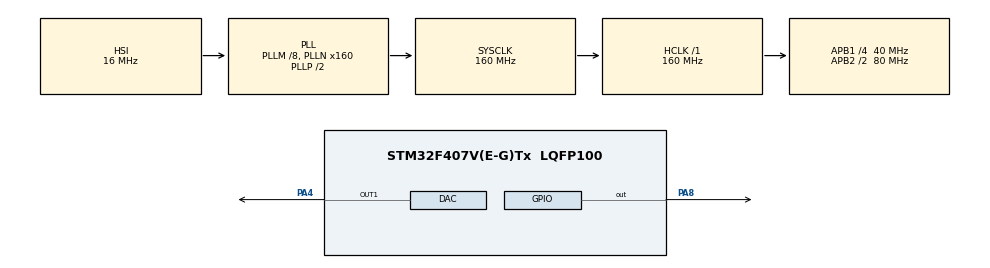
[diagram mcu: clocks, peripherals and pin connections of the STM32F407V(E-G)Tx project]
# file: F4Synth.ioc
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Mcu.Family=STM32F4
Mcu.Name=STM32F407V(E-G)Tx
Mcu.Package=LQFP100
NVIC.PriorityGroup=NVIC_PRIORITYGROUP_4
NVIC.TIM3_IRQn=true\:0\:0\:false\:false\:true\:true\:true\:true
PA13.Mode=Serial_Wire
PA13.Signal=SYS_JTMS-SWDIO
PA14.Mode=Serial_Wire
PA14.Signal=SYS_JTCK-SWCLK
PA4.Signal=COMP_DAC1_group
PA8.Signal=GPIO_Output
PH0-OSC_IN.Mode=HSE-External-Oscillator
PH0-OSC_IN.Signal=RCC_OSC_IN
PH1-OSC_OUT.Mode=HSE-External-Oscillator
PH1-OSC_OUT.Signal=RCC_OSC_OUT
ProjectManager.HeapSize=0x200
ProjectManager.StackSize=0x400
ProjectManager.TargetToolchain=MDK-ARM V5.32
RCC.48MHZClocksFreq_Value=80000000
RCC.AHBFreq_Value=160000000
RCC.APB1CLKDivider=RCC_HCLK_DIV4
RCC.APB1Freq_Value=40000000
RCC.APB1TimFreq_Value=80000000
RCC.APB2CLKDivider=RCC_HCLK_DIV2
RCC.APB2Freq_Value=80000000
RCC.APB2TimFreq_Value=160000000
RCC.CortexFreq_Value=160000000
RCC.HCLKFreq_Value=160000000
RCC.HSE_VALUE=8000000
RCC.HSI_VALUE=16000000
RCC.LSE_VALUE=32768
RCC.PLLM=8
RCC.PLLN=160
RCC.SYSCLKFreq_VALUE=160000000
RCC.SYSCLKSource=RCC_SYSCLKSOURCE_PLLCLK
RCC.VCOOutputFreq_Value=320000000
SH.COMP_DAC1_group.0=DAC_OUT1,DAC_OUT1
TIM3.Channel-Output\ Compare1\ No\ Output=TIM_CHANNEL_1
TIM3.OCMode_1=TIM_OCMODE_TOGGLE
TIM3.Period=100-1
TIM3.Prescaler=40-1
VP_TIM3_VS_ClockSourceINT.Mode=Internal
VP_TIM3_VS_no_output1.Mode=Output Compare1 No Output
board=custom

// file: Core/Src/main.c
/* USER CODE BEGIN Header */
/**
  ******************************************************************************
  * @file           : main.c
  * @brief          : Main program body
  ******************************************************************************
  * @attention
  *
  * Copyright (c) 2024 STMicroelectronics.
  * All rights reserved.
  *
  * This software is licensed under terms that can be found in the LICENSE file
  * in the root directory of this software component.
  * If no LICENSE file comes with this software, it is provided AS-IS.
  *
  ******************************************************************************
  */
/* USER CODE END Header */
#include "main.h"
#include "dac.h"
#include "tim.h"
#include "gpio.h"

/* USER CODE BEGIN Includes */
#include "SYNTH.h"
#include "MIDI.H"
/* USER CODE END Includes */

void SystemClock_Config(void);
/* USER CODE BEGIN PFP */
//波表合成器
//ch表示MIDI通道序号
u32 Synth_GM(const u32 MIDI[], u8 ch
	, struct MIDI_CTRL midi_ctrl[], struct VCO VCO1[], struct ADSR ADSR1[])
{
    MIDI_Control(&midi_ctrl[ch], MIDI, &ADSR1[ch].ADSR_in);
    VCO1[ch].VCO_freq = midi_ctrl[ch].mid_freq;
    VCO_gen(&VCO1[ch]);
    ADSR(&ADSR1[ch]);
    u32 amp = midi_ctrl[ch].mid_vec * ADSR1[ch].ADSR_out / 10000;
    return amp * (VCO1[ch].VCO_Out)  / 256;
}

//采样播放器
//midi_ch表示MIDI通道序号
//sample_ch表示采样通道序号
u32 Synth_SA(const u32 MIDI[], u8 midi_ch, struct MIDI_CTRL midi_ctrl[],
				 struct SampleCTRL SaCt1[], u8 sample_ch, const s8 Sample_Audio[], u32 Sample_len)
{
	SaCt1[sample_ch].max_len = Sample_len;

    MIDI_Control(&midi_ctrl[midi_ch], MIDI, &SaCt1[sample_ch].trig);
    return Sample(Sample_Audio, &SaCt1[sample_ch]);
}
/* USER CODE END PFP */

/* USER CODE BEGIN 0 */
extern const signed char SnareTable[6000];
extern const signed char CrashTable[17500];
extern const signed char TomsTable[10000];
extern const signed char TambourineTable[10000];
extern const signed char Tambourine2Table[15000];
extern const unsigned int MIDI_1[];
extern const unsigned int MIDI_2[];
extern const unsigned int MIDI_3[];
extern const unsigned int MIDI_4[];
extern const unsigned int MIDI_5[];
extern const unsigned int MIDI_6[];
extern const unsigned int MIDI_7[];

unsigned int i = 0;
struct SampleCTRL SaCt1[4];
struct MIDI_CTRL midi_ctrl[8];
struct VCO VCO_1[4];
struct ADSR ADSR_1[4];
/* USER CODE END 0 */

int main(void)
{

    /* MCU Configuration--------------------------------------------------------*/

    /* Reset of all peripherals, Initializes the Flash interface and the Systick. */
    HAL_Init();

    /* Configure the system clock */
    SystemClock_Config();

    /* Initialize all configured peripherals */
    MX_GPIO_Init();
    MX_DAC_Init();
    MX_TIM3_Init();
    /* USER CODE BEGIN 2 */
    HAL_DAC_MspInit(&hdac);
    HAL_TIM_Base_MspInit(&htim3);
    HAL_TIM_Base_Start_IT(&htim3);
    /* USER CODE END 2 */

    /* Infinite loop */
    /* USER CODE BEGIN WHILE */
    SaCtInit(SaCt1, 4);

    MIDI_CTRL_INIT(midi_ctrl, 8);

    VCO_1[0].idx = 0;
    VCO_1[0].phase = 1;
    VCO_1[0].VCO_wavetype = 4;
    VCO_1[1].idx = 0;
    VCO_1[1].phase = 1;
    VCO_1[1].VCO_wavetype = 0;
	VCO_1[2].idx = 0;
    VCO_1[2].phase = 1;
    VCO_1[2].VCO_wavetype = 0;
    VCO_1[3].idx = 0;
    VCO_1[3].phase = 1;
    VCO_1[3].VCO_wavetype = 3;

    {
        ADSR_1[0].ADSR_enable = 1;
        ADSR_1[0].ADSR_statu = 0;
        ADSR_1[0].ADSR_count = 0;
        ADSR_1[0].A_time = 5;
        ADSR_1[0].A_speed = 2000;
        ADSR_1[0].D_time = 3000;
        ADSR_1[0].D_speed = 3;
        ADSR_1[0].R_time = 0;
        ADSR_1[0].R_speed = 0;
        ADSR_1[0].velocity = 255;
        ADSR_1[1].ADSR_enable = 1;
        ADSR_1[1].ADSR_statu = 0;
        ADSR_1[1].ADSR_count = 0;
        ADSR_1[1].A_time = 5;
        ADSR_1[1].A_speed = 2000;
        ADSR_1[1].D_time = 3000;
        ADSR_1[1].D_speed = 0;
        ADSR_1[1].R_time = 0;
        ADSR_1[1].R_speed = 0;
        ADSR_1[1].velocity = 255;
		ADSR_1[2].ADSR_enable = 1;
        ADSR_1[2].ADSR_statu = 0;
        ADSR_1[2].ADSR_count = 0;
        ADSR_1[2].A_time = 5;
        ADSR_1[2].A_speed = 2000;
        ADSR_1[2].D_time = 3000;
        ADSR_1[2].D_speed = 0;
        ADSR_1[2].R_time = 0;
        ADSR_1[2].R_speed = 0;
        ADSR_1[2].velocity = 255;
		ADSR_1[3].ADSR_enable = 1;
        ADSR_1[3].ADSR_statu = 0;
        ADSR_1[3].ADSR_count = 0;
        ADSR_1[3].A_time = 5;
        ADSR_1[3].A_speed = 2000;
        ADSR_1[3].D_time = 3000;
        ADSR_1[3].D_speed = 0;
        ADSR_1[3].R_time = 0;
        ADSR_1[3].R_speed = 0;
        ADSR_1[3].velocity = 255;
    }

    while (1)
    {
        /* USER CODE END WHILE */

    }
}

void SystemClock_Config(void)
{
    RCC_OscInitTypeDef RCC_OscInitStruct = {0};
    RCC_ClkInitTypeDef RCC_ClkInitStruct = {0};

    /** Configure the main internal regulator output voltage
    */
    __HAL_RCC_PWR_CLK_ENABLE();
    __HAL_PWR_VOLTAGESCALING_CONFIG(PWR_REGULATOR_VOLTAGE_SCALE1);

    /** Initializes the RCC Oscillators according to the specified parameters
    * in the RCC_OscInitTypeDef structure.
    */
    RCC_OscInitStruct.OscillatorType = RCC_OSCILLATORTYPE_HSI;
    RCC_OscInitStruct.HSIState = RCC_HSI_ON;
    RCC_OscInitStruct.HSICalibrationValue = RCC_HSICALIBRATION_DEFAULT;
    RCC_OscInitStruct.PLL.PLLState = RCC_PLL_ON;
    RCC_OscInitStruct.PLL.PLLSource = RCC_PLLSOURCE_HSI;
    RCC_OscInitStruct.PLL.PLLM = 8;
    RCC_OscInitStruct.PLL.PLLN = 160;
    RCC_OscInitStruct.PLL.PLLP = RCC_PLLP_DIV2;
    RCC_OscInitStruct.PLL.PLLQ = 4;
    if (HAL_RCC_OscConfig(&RCC_OscInitStruct) != HAL_OK)
    {
        Error_Handler();
    }

    /** Initializes the CPU, AHB and APB buses clocks
    */
    RCC_ClkInitStruct.ClockType = RCC_CLOCKTYPE_HCLK|RCC_CLOCKTYPE_SYSCLK
                                  |RCC_CLOCKTYPE_PCLK1|RCC_CLOCKTYPE_PCLK2;
    RCC_ClkInitStruct.SYSCLKSource = RCC_SYSCLKSOURCE_PLLCLK;
    RCC_ClkInitStruct.AHBCLKDivider = RCC_SYSCLK_DIV1;
    RCC_ClkInitStruct.APB1CLKDivider = RCC_HCLK_DIV4;
    RCC_ClkInitStruct.APB2CLKDivider = RCC_HCLK_DIV2;

    if (HAL_RCC_ClockConfig(&RCC_ClkInitStruct, FLASH_LATENCY_5) != HAL_OK)
    {
        Error_Handler();
    }
}

/* USER CODE BEGIN 4 */
void HAL_TIM_PeriodElapsedCallback(TIM_HandleTypeDef *htim)
{
	u32 SampleLen = 0;

    if(htim == &htim3)	//TIM3 MIDI音序触发定时
    {
        HAL_GPIO_TogglePin(GPIOA, GPIO_PIN_8);

        u32 out1 = Synth_GM(MIDI_1, 0, midi_ctrl, VCO_1, ADSR_1);
        u32 out2 = Synth_GM(MIDI_2, 1, midi_ctrl, VCO_1, ADSR_1);
		u32 out3 = Synth_GM(MIDI_3, 2, midi_ctrl, VCO_1, ADSR_1);
        u32 out4 = Synth_GM(MIDI_4, 3, midi_ctrl, VCO_1, ADSR_1);

		SampleLen = sizeof(SnareTable);
        u32 out5 = Synth_SA(MIDI_5, 4, midi_ctrl, SaCt1, 0, SnareTable, SampleLen);
		SampleLen = sizeof(TomsTable);
        u32 out6 = Synth_SA(MIDI_6, 5, midi_ctrl, SaCt1, 1, TomsTable, SampleLen);
		SampleLen = sizeof(CrashTable);
		u32 out7 = Synth_SA(MIDI_7, 6, midi_ctrl, SaCt1, 2, CrashTable, SampleLen);

        u32 output = 4096 / 2 + (out1 + out4) * 10 + (out5 + out6 + out7 + out2 + out3) * 5;

        HAL_DAC_SetValue(&hdac, DAC_CHANNEL_1, DAC_ALIGN_12B_R, output);
        HAL_DAC_Start(&hdac, DAC_CHANNEL_1);

        //u32 output = 4096 / 2 + (midi_ctrl.mid_vec * Sample(SnareTable, &SaCt1[0]) / 127);
    }
}
/* USER CODE END 4 */

void Error_Handler(void)
{
    __disable_irq();
    while (1)
    {
    }
}
